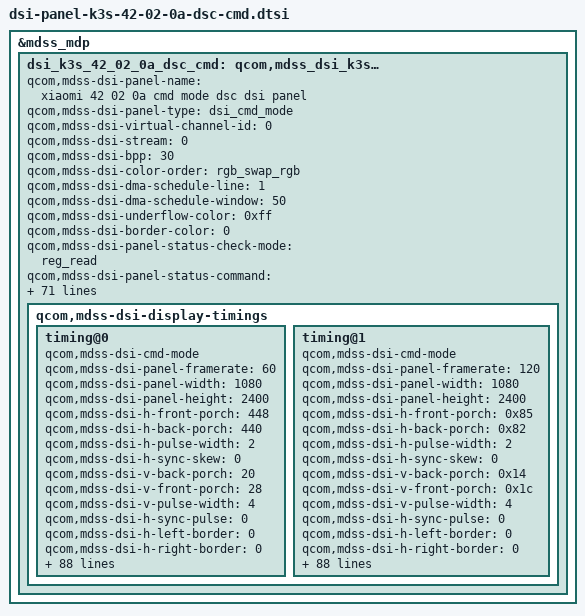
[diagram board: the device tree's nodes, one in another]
&mdss_mdp {
	dsi_k3s_42_02_0a_dsc_cmd: qcom,mdss_dsi_k3s_42_02_0a_dsc_cmd {
		qcom,mdss-dsi-panel-name = "xiaomi 42 02 0a cmd mode dsc dsi panel";
		qcom,mdss-dsi-panel-type = "dsi_cmd_mode";
		qcom,mdss-dsi-virtual-channel-id = <0>;
		qcom,mdss-dsi-stream = <0>;
		qcom,mdss-dsi-bpp = <30>;
		qcom,mdss-dsi-color-order = "rgb_swap_rgb";
		qcom,mdss-dsi-dma-schedule-line = <1>;
		qcom,mdss-dsi-dma-schedule-window = <50>;
		qcom,mdss-dsi-underflow-color = <0xff>;
		qcom,mdss-dsi-border-color = <0>;

		qcom,mdss-dsi-panel-status-check-mode = "reg_read";
		qcom,mdss-dsi-panel-status-command = <0x6010001 0x1fa 0x6010001 0x191>;
		qcom,mdss-dsi-panel-status-command-state = "dsi_lp_mode";
		qcom,mdss-dsi-panel-status-offset-command = [39 01 00 00 00 00 05 ff aa 55 a5 81 39 01 00 00 00 00 02 6f 0f];
		qcom,mdss-dsi-panel-status-offset-command-state = "dsi_lp_mode";
		qcom,mdss-dsi-panel-status-read-length = <0x01 0x12>;
		qcom,mdss-dsi-panel-status-value = <0 171 168
						0 12 194
						0 3 28 1 126
						0 15 8 187 4 61 16 240>;

		qcom,dsi-ctrl-num = <0>;
		qcom,dsi-phy-num = <0>;

		qcom,mdss-dsi-traffic-mode = "burst_mode";
		qcom,suspend-ulps-enabled;
		qcom,mdss-dsi-lane-map = "lane_map_0123";
		qcom,mdss-dsi-bllp-eof-power-mode;
		qcom,mdss-dsi-bllp-power-mode;
		qcom,mdss-dsi-lane-0-state;
		qcom,mdss-dsi-lane-1-state;
		qcom,mdss-dsi-lane-2-state;
		qcom,mdss-dsi-lane-3-state;
		qcom,mdss-dsi-dma-trigger = "trigger_sw";
		qcom,mdss-dsi-mdp-trigger = "none";
		qcom,mdss-dsi-reset-sequence = <0 10>, <1 10>, <0 1>, <1 10>;
		qcom,mdss-pan-physical-width-dimension = <695>;
		qcom,mdss-pan-physical-height-dimension = <1545>;
		qcom,mdss-dsi-te-pin-select = <1>;
		qcom,mdss-dsi-wr-mem-start = <0x2c>;
		qcom,mdss-dsi-wr-mem-continue = <0x3c>;
		qcom,mdss-dsi-te-dcs-command = <1>;
		qcom,mdss-dsi-te-check-enable;
		qcom,mdss-dsi-te-using-te-pin;
		qcom,mdss-dsi-tx-eot-append;
		qcom,mdss-dsi-lp11-init;

		qcom,mdss-dsi-panel-mode-switch;

		qcom,mdss-dsi-panel-max-error-count = <3>;

		qcom,mdss-dsi-bl-inverted-dbv;
		qcom,bl-update-flag = "delay_until_first_frame";

		qcom,mdss-dsi-panel-hdr-enabled;
		qcom,mdss-dsi-panel-hdr-color-primaries = <14500 15500 32000
			17000 15500 30000 8000 3000>;
		qcom,mdss-dsi-panel-peak-brightness = <4200000>;
		qcom,mdss-dsi-panel-blackness-level = <3230>;

		qcom,mdss-dsi-display-timings {
			timing@0 {
				qcom,mdss-dsi-cmd-mode;
				qcom,mdss-dsi-panel-framerate = <60>;
				qcom,mdss-dsi-panel-width = <1080>;
				qcom,mdss-dsi-panel-height = <2400>;
				qcom,mdss-dsi-h-front-porch = <448>;
				qcom,mdss-dsi-h-back-porch = <440>;
				qcom,mdss-dsi-h-pulse-width = <2>;
				qcom,mdss-dsi-h-sync-skew = <0>;
				qcom,mdss-dsi-v-back-porch = <20>;
				qcom,mdss-dsi-v-front-porch = <28>;
				qcom,mdss-dsi-v-pulse-width = <4>;
				qcom,mdss-dsi-h-sync-pulse = <0>;
				qcom,mdss-dsi-h-left-border = <0>;
				qcom,mdss-dsi-h-right-border = <0>;
				qcom,mdss-dsi-v-top-border = <0>;
				qcom,mdss-dsi-v-bottom-border = <0>;
				qcom,mdss-dsi-panel-clockrate = <1100000000>;
				qcom,mdss-dsi-panel-jitter = <0x5 0x1>;
				qcom,mdss-mdp-transfer-time-us = <14000>;
				qcom,mdss-dsi-on-command = [
					39 01 00 00 00 00 06 f0 55 aa 52 08 00 39 01 00 00 00 00 02 6f 05 39 01 00 00 00 00 02 be 08 39 01 00 00 00 00 02 90 01 39 01 00 00 00 00 13 91 ab a8 00 0c c2 00 03 1c 01 7e 00 0f 08 bb 04 3d 10 f0 39 01 00 00 00 00 02 03 01 39 01 00 00 00 00 02 2c 00 39 01 00 00 00 00 06 f0 55 aa 52 08 07 39 01 00 00 00 00 03 c0 01 02 39 01 00 00 00 00 02 35 00 39 01 00 00 00 00 05 2a 00 00 04 37 39 01 00 00 00 00 05 2b 00 00 09 5f 39 01 00 00 00 00 02 53 28 39 00 00 00 00 00 06 f0 55 aa 52 08 00 39 00 00 00 00 00 02 6f 02 39 01 00 00 00 00 03 b2 08 08 39 01 00 00 00 00 02 2f 01 39 01 00 00 00 00 06 f0 55 aa 52 08 01 39 01 00 00 00 00 08 c3 9b 01 94 d0 22 02 00 39 01 00 00 00 00 06 f0 55 aa 52 08 00 39 01 00 00 00 00 02 6f 06 39 01 00 00 00 00 04 b5 2b 0c 32 39 01 00 00 78 00 02 11 00 39 01 00 00 00 00 02 29 00
				];
				qcom,mdss-dsi-on-command-state = "dsi_lp_mode";

				qcom,mdss-dsi-nolp-command = <0x39010000 0x551 0x00 0x39000000 0x6f0 0x55aa5208 0x390000 0x02 0xb2183900 0x00 0x2650039 0x00 0x23800 0x39000000 0x22c 0x390000 0x02 0x2f013900 0x00 0x6f055aa 0x52080139 0x1000000 0x2ce0c>;
				qcom,mdss-dsi-nolp-command-state = "dsi_lp_mode";
				qcom,mdss-dsi-off-command = [
					39 01 00 00 00 00 02 28 00 39 01 00 00 64 00 02 10 00
				];
				qcom,mdss-dsi-off-command-state = "dsi_lp_mode";

				qcom,mdss-dsi-panel-phy-timings = [00 24 0a 0a 1a 24 0a 0a 0a 09 02 04 1e 0f];
				qcom,mdss-dsi-timing-switch-command = [
					/* Frame Rate 60Hz */
					39 01 00 00 09 00 02 2f 01
				];
				qcom,mdss-dsi-timing-switch-command-state = "dsi_lp_mode";

				qcom,default-topology-index = <0>;
				qcom,display-topology = <1 1 1>;

				qcom,compression-mode = "dsc";
				qcom,mdss-dsc-version = <18>;
				qcom,mdss-dsc-scr-version = <0>;
				qcom,mdss-dsc-slice-height = <12>;
				qcom,mdss-dsc-slice-width = <1080>;
				qcom,mdss-dsc-slice-per-pkt = <2>;
				qcom,mdss-dsc-bit-per-component = <10>;
				qcom,mdss-dsc-bit-per-pixel = <8>;
				qcom,mdss-dsc-block-prediction-enable;
			};
			timing@1 {
				qcom,mdss-dsi-cmd-mode;
				qcom,mdss-dsi-panel-framerate = <120>;
				qcom,mdss-dsi-panel-width = <1080>;
				qcom,mdss-dsi-panel-height = <2400>;
				qcom,mdss-dsi-h-front-porch = <0x85>;
				qcom,mdss-dsi-h-back-porch = <0x82>;
				qcom,mdss-dsi-h-pulse-width = <2>;
				qcom,mdss-dsi-h-sync-skew = <0>;
				qcom,mdss-dsi-v-back-porch = <0x14>;
				qcom,mdss-dsi-v-front-porch = <0x1c>;
				qcom,mdss-dsi-v-pulse-width = <4>;
				qcom,mdss-dsi-h-sync-pulse = <0>;
				qcom,mdss-dsi-h-left-border = <0>;
				qcom,mdss-dsi-h-right-border = <0>;
				qcom,mdss-dsi-v-top-border = <0>;
				qcom,mdss-dsi-v-bottom-border = <0>;
				qcom,mdss-dsi-panel-clockrate = <1100000000>;
				qcom,mdss-dsi-panel-jitter = <0x5 0x1>;
				qcom,mdss-mdp-transfer-time-us = <7000>;
				qcom,mdss-dsi-on-command = [
					39 01 00 00 00 00 06 f0 55 aa 52 08 00 39 01 00 00 00 00 02 6f 05 39 01 00 00 00 00 02 be 08 39 01 00 00 00 00 02 90 01 39 01 00 00 00 00 13 91 ab a8 00 0c c2 00 03 1c 01 7e 00 0f 08 bb 04 3d 10 f0 39 01 00 00 00 00 02 03 01 39 01 00 00 00 00 02 2c 00 39 01 00 00 00 00 06 f0 55 aa 52 08 07 39 01 00 00 00 00 03 c0 01 02 39 01 00 00 00 00 02 35 00 39 01 00 00 00 00 05 2a 00 00 04 37 39 01 00 00 00 00 05 2b 00 00 09 5f 39 01 00 00 00 00 02 53 28 39 00 00 00 00 00 06 f0 55 aa 52 08 00 39 00 00 00 00 00 02 6f 02 39 01 00 00 00 00 03 b2 08 08 39 01 00 00 00 00 02 2f 02 39 01 00 00 00 00 06 f0 55 aa 52 08 01 39 01 00 00 00 00 08 c3 9b 01 94 d0 22 02 00 39 01 00 00 00 00 06 f0 55 aa 52 08 00 39 01 00 00 00 00 02 6f 06 39 01 00 00 00 00 04 b5 2b 0c 32 39 01 00 00 78 00 02 11 00 39 01 00 00 00 00 02 29 00
				];
				qcom,mdss-dsi-on-command-state = "dsi_lp_mode";

				qcom,mdss-dsi-off-command = [
					39 01 00 00 00 00 02 28 00
					39 01 00 00 64 00 02 10 00];
				qcom,mdss-dsi-off-command-state = "dsi_lp_mode";

				qcom,mdss-dsi-timing-switch-command = [
					/* Frame Rate 90Hz */
					39 01 00 00 11 00 02 2f 02
				];
				qcom,mdss-dsi-timing-switch-command-state = "dsi_lp_mode";

				qcom,compression-mode = "dsc";
				qcom,mdss-dsc-version = <18>;
				qcom,mdss-dsc-scr-version = <0x0>;
				qcom,mdss-dsi-panel-phy-timings = [00 24 0a 0a 1a 19 09 0a 0a 09 02 04 1e 0f];
				qcom,mdss-dsc-slice-height = <12>;
				qcom,mdss-dsc-slice-width = <1080>;
				qcom,mdss-dsc-slice-per-pkt = <2>;
				qcom,mdss-dsc-bit-per-component = <10>;
				qcom,mdss-dsc-bit-per-pixel = <8>;
				qcom,mdss-dsc-block-prediction-enable;
				qcom,default-topology-index = <0x00>;
				qcom,display-topology = <1 1 1>;
				qcom,mdss-dsi-nolp-command = <0x39010000 0x551 0x00 0x39000000 0x6f0 0x55aa5208 0x390000 0x02 0xb2183900 0x00 0x2650039 0x00 0x23800 0x39000000 0x22c 0x390000 0x02 0x2f023900 0x00 0x6f055aa 0x52080139 0x1000000 0x2ce0c>;
				qcom,mdss-dsi-nolp-command-state = "dsi_lp_mode";
			};
		};
	};
};

&dsi_k3s_42_02_0a_dsc_cmd {
	mi,panel-id = <0x00004B3353 0x0000420200>;
	mi,hbm-51-ctl-flag;
	mi,hbm-off-51-index = <0>;
	mi,hbm-on-51-index = <0>;
	mi,hbm-bl-min-level = <1>;
	mi,hbm-bl-max-level = <2047>;
	mi,max-brightness-clone = <8191>;
	// mi,fp-display-on-optimize-flag;
	mi,aod-hbm-51-index = <8>;
	mi,aod-lbm-51-index = <8>;
	mi,mdss-dsi-panel-dc-type = <0>;
	mi,dc-off-120hz-d4-index = <7>;
	mi,dc-off-60hz-d2-index = <6>;
	mi,dc-on-120hz-d4-index = <11>;
	mi,dc-on-60hz-d2-index = <10>;

	mi,dc-update-flag;
	mi,esd-err-irq-gpio = <&tlmm 75 8193>;
	mi,flatmode-on-b9-index = <0x03>;
	mi,flatmode-update-flag;
	mi,fp-display-on-optimize-flag;
	//mi,panel-hbm-backlight-threshold = <2047>;
	//mi,panel-cup-dbi-reg-index = <1>;

	mi,panel-on-dimming-delay = <120>;

	mi,panel-aod-to-off-command-need-enabled;
	//mi,thermal-dimming-flag;

	qcom,dsi-select-clocks = "mux_byte_clk0", "mux_pixel_clk0";
	qcom,mdss-dsi-clk-strength = <101>;
	qcom,esd-aod-check-enabled;
	qcom,esd-check-enabled;

	qcom,mdss-dsi-display-timings {
		timing@0 {
			mi,mdss-dsc-panel-id = <0x00004B3353 0x00420200>;
			mi,mdss-dsi-dimmingon-command = [39 01 00 00 00 00 02 53 28];
			mi,mdss-dsi-dimmingon-command-state = "dsi_hs_mode";
			mi,mdss-dsi-dimmingoff-command = [39 01 00 00 00 00 02 53 20];
			mi,mdss-dsi-dimmingoff-command-state = "dsi_hs_mode";

			mi,mdss-dsi-hbm-on-command = [39 01 00 00 00 00 03 51 0F FF];
			mi,mdss-dsi-hbm-on-command-state = "dsi_lp_mode";
			mi,mdss-dsi-hbm-off-command = [39 01 00 00 00 00 03 51 07 FF];
			mi,mdss-dsi-hbm-off-command-state = "dsi_lp_mode";

			mi,mdss-dsi-doze-hbm-command = [
				/* Frame Rate 60Hz */
				39 01 00 00 00 00 02 2f 01
				39 00 00 00 00 00 06 f0 55 aa 52 08 08
				39 00 00 00 00 00 02 6f 07
				39 00 00 00 00 00 05 b9 00 00 00 3d
				39 00 00 00 00 00 06 f0 55 aa 52 08 00
				39 00 00 00 00 00 02 b2 08
				39 01 00 00 32 00 02
				39 00 39 00 00 00 00 00 02 65 01
				39 01 00 00 00 00 05 51 01 06 0f ff
			];
			mi,mdss-dsi-doze-hbm-command-state = "dsi_lp_mode";
			mi,mdss-dsi-doze-lbm-command = [
				/* Frame Rate 60Hz */
				39 01 00 00 00 00 02 2f 01 39 00 00 00 00 00 06 f0 55 aa 52 08 08 39 00 00 00 00 00 02 6f 07 39 00 00 00 00 00 05 b9 00 00 00 3d 39 00 00 00 00 00 06 f0 55 aa 52 08 00 39 00 00 00 00 00 02 b2 08 39 01 00 00 32 00 02 39 00 39 00 00 00 00 00 02 65 01 39 01 00 00 00 00 05 51 00 24 01 55
			];
			mi,mdss-dsi-doze-lbm-command-state = "dsi_lp_mode";

			mi,mdss-dsi-flat-mode-on-command = [
				39 00 00 00 00 00 02 2f 03 39 00 00 00 00 00 06 f0 55 aa 52 08 08 39 00 00 00 00 00 02 6f 07 39 00 00 00 00 00 05 b9 00 00 00 00 39 00 00 00 00 00 06 f0 55 aa 52 08 00 39 00 00 00 00 00 02 6f 08 39 01 00 00 00 00 02 c0 44
			];
			mi,mdss-dsi-flat-mode-on-command-state = "dsi_hs_mode";
			mi,mdss-dsi-flat-mode-off-command = [
				39 00 00 00 00 00 02 2f 01 39 00 00 00 00 00 06 f0 55 aa 52 08 08 39 00 00 00 00 00 02 6f 07 39 00 00 00 00 00 05 b9 00 00 00 3d 39 00 00 00 00 00 06 f0 55 aa 52 08 00 39 00 00 00 00 00 02 6f 08 39 01 00 00 00 00 02 c0 40
			];
			mi,mdss-dsi-flat-mode-off-command-state = "dsi_hs_mode";

			mi,mdss-dsi-flat-mode-read-pre-command = [39 01 00 00 00 00 06 f0 55 aa 52 08 00 39 01 00 00 00 00 02 6f 3f];
			mi,mdss-dsi-flat-mode-read-pre-command-state = "dsi_lp_mode";

			mi,mdss-dsi-aod-to-dc-on-command = [
				39 01 00 00 00 00 06 f0 55 aa 52 08 00
				39 01 00 00 00 00 02 b2 98
			];
			mi,mdss-dsi-aod-to-dc-on-command-state = "dsi_hs_mode";

			mi,mdss-dsi-dc-on-command = [
				39 01 00 00 00 00 06 f0 55 aa 52 08 00
				39 00 00 00 00 00 02 b2 98
				39 00 00 00 00 00 02 6f 0f
				39 00 00 00 00 00 09 b2 00 00 01 47 01 47 00 00
				39 00 00 00 00 00 25 b3 00
							00 00 00 00 00 00 00 00
							00 00 00 00 00 00 00 00
							00 00 00 00 00 00 00 00
							00 00 00 00 00 00 00 07 ff 0f ff
				39 00 00 00 00 00 02 6f ac
				39 00 00 00 00 00 47 b2 00
				00 01 0a 01 6c 01 b6 01 f3
				02 28 02 58 02 84 02 ac 02
				d2 02 f5 03 17 03 37 04 e0
				06 09 06 fa 07 c9 08 81 09
				28 09 c1 0a 51 0a d7 0b 56
				0b cf 0c 42 0c b0 0d 1a 0d
				80 0d e3 0e 42 0e 9f 0e f9
				0f 50 0f a5 0f ff
				39 00 00 00 00 00 02 6f 52
				39 00 00 00 00 00 45 b3 00 05 00 0a 00 0f 00 14 00 19 00 1e 00 23 00 28 00 2d 00 32 00 37 00 3c 00 96 00 f0 01 4a 01 a4 01 fe 02 58 02 b2 03 0c 03 66 03 c0 04 1a 04 74 04 ce 05 28 05 82 05 dc 06 36 06 90 06 ea 07 44 07 9e 07 ff
				39 00 00 00 00 00 06 f0 55 aa 52 08 04
				39 00 00 00 00 00 4c d2 00 00 00 00 00 00 00 00 00 00 00 00 00 00 00 00 00 00 00 00 00 00 00 00 00 00 00 00 00 00 00 00 00 00 00 00 00 00 00 00 00 00 00 00 00 00 00 00 00 00 00 00 00 00 00 00 00 00 00 00 00 00 00 00 00 00 00 00 00 00 00 00 00 00 00
				39 01 00 00 00 00 4c d4 00 00 00 00 00 00 00 00 00 00 00 00 00 00 00 00 00 00 00 00 00 00 00 00 00 00 00 00 00 00 00 00 00 00 00 00 00 00 00 00 00 00 00 00 00 00 00 00 00 00 00 00 00 00 00 00 00 00 00 00 00 00 00 00 00 00 00 00 00 00 00 00 00 00 00
			];
			mi,mdss-dsi-dc-on-command-state = "dsi_lp_mode";
			mi,mdss-dsi-dc-off-command = [
				39 01 00 00 00 00 06 f0 55 aa 52 08 00
				39 00 00 00 00 00 02 b2 18
				39 00 00 00 00 00 02 6f 0f
				39 00 00 00 00 00 09 b2 20 20 21 47 21 47 20 00
				39 00 00 00 00 00 25 b3 00 08 00 18 00 18 00
				31 00 31 00 62 00 62 00 c0 00 c0 01 32 01 32 01 47 01 47 03 33 03 33 07 ff 07 ff 0f ff
				39 00 00 00 00 00 06 f0 55 aa 52 08 04
				39 00 00 00 00 00 4c d2
				00 00 00 00 00 00 00 00
				00 00 00 00 00 00 00 00
				00 00 00 00 00 00 00 00
				00 00 00 00 00 00 00 00
				00 00 00 00 00 00 00 00
				00 00 00 00 00 00 00 00
				00 00 00 00 00 00 00 00
				00 00 00 00 00 00 00 00
				00 00 00 00 00 00 00 00 00 00 00
				39 01 00 00 00 00 4c d4 00 00 00
				00 00 00 00 00 00 00 00
				00 00 00 00 00 00 00 00
				00 00 00 00 00 00 00 00
				00 00 00 00 00 00 00 00
				00 00 00 00 00 00 00 00
				00 00 00 00 00 00 00 00
				00 00 00 00 00 00 00 00
				00 00 00 00 00 00 00 00
				00 00 00 00 00 00 00 00
			];
			mi,mdss-dsi-dc-off-command-state = "dsi_lp_mode";

			mi,mdss-dsi-pre-doze-to-off-command = [39 01 00 00 00 00 06 f0 55 aa 52 08 01 39 01 00 00 00 00 02 ce 0c];
			mi,mdss-dsi-pre-doze-to-off-command-state = "dsi_lp_mode";
			mi,mdss-dsi-switch-page4-command = [39 01 00 00 00 00 06 f0 55 aa 52 08 04];
			mi,mdss-dsi-switch-page4-command-state = "dsi_lp_mode";
			mi,mdss-dsi-timing-switch-gir-command = [39 01 00 00 09 00 02 2f 03];
			mi,mdss-dsi-timing-switch-gir-command-state = "dsi_hs_mode";
		};
		timing@1 {
			mi,mdss-dsc-panel-id = <0x00004B3353 0x00420200>;
			mi,mdss-dsi-dimmingon-command = [39 01 00 00 00 00 02 53 28];
			mi,mdss-dsi-dimmingon-command-state = "dsi_hs_mode";
			mi,mdss-dsi-dimmingoff-command = [39 01 00 00 00 00 02 53 20];
			mi,mdss-dsi-dimmingoff-command-state = "dsi_hs_mode";

			mi,mdss-dsi-aod-to-dc-on-command = [39 01 00 00 00 00 06 f0 55 aa 52 08 00 39 01 00 00 00 00 02 b2 98];
			mi,mdss-dsi-aod-to-dc-on-command-state = "dsi_hs_mode";

			mi,mdss-dsi-doze-hbm-command = [
				/* Frame Rate 60Hz */
				39 01 00 00 00 00 02 2f 01 39 00 00 00 00 00 06 f0 55 aa 52 08 08 39 00 00 00 00 00 02 6f 07 39 00 00 00 00 00 05 b9 00 00 00 3d 39 00 00 00 00 00 06 f0 55 aa 52 08 00 39 00 00 00 00 00 02 b2 08 39 01 00 00 32 00 02 39 00 39 00 00 00 00 00 02 65 01 39 01 00 00 00 00 05 51 01 06 0f ff
			];
			mi,mdss-dsi-doze-hbm-command-state = "dsi_lp_mode";
			mi,mdss-dsi-doze-lbm-command = [
				/* Frame Rate 60Hz */
				39 01 00 00 00 00 02 2f 01 39 00 00 00 00 00 06 f0 55 aa 52 08 08 39 00 00 00 00 00 02 6f 07 39 00 00 00 00 00 05 b9 00 00 00 3d 39 00 00 00 00 00 06 f0 55 aa 52 08 00 39 00 00 00 00 00 02 b2 08 39 01 00 00 32 00 02 39 00 39 00 00 00 00 00 02 65 01 39 01 00 00 00 00 05 51 00 24 01 55
			];

			mi,mdss-dsi-hbm-off-command = [39 01 00 00 00 00 03 51 07 ff];
			mi,mdss-dsi-hbm-off-command-state = "dsi_lp_mode";
			mi,mdss-dsi-hbm-on-command = [39 01 00 00 00 00 03 51 0f ff];
			mi,mdss-dsi-hbm-on-command-state = "dsi_lp_mode";

			mi,mdss-dsi-doze-lbm-command-state = "dsi_lp_mode";

			mi,mdss-dsi-flat-mode-on-command = [
				39 00 00 00 00 00 02 2f 04 39 00 00 00 00 00 06 f0 55 aa 52 08 08 39 00 00 00 00 00 02 6f 07 39 00 00 00 00 00 05 b9 00 00 00 00 39 00 00 00 00 00 06 f0 55 aa 52 08 00 39 00 00 00 00 00 02 6f 08 39 01 00 00 00 00 02 c0 44
			];
			mi,mdss-dsi-flat-mode-on-command-state = "dsi_hs_mode";
			mi,mdss-dsi-flat-mode-off-command = [
				39 00 00 00 00 00 02 2f 02 39 00 00 00 00 00 06 f0 55 aa 52 08 08 39 00 00 00 00 00 02 6f 07 39 00 00 00 00 00 05 b9 00 00 00 3d 39 00 00 00 00 00 06 f0 55 aa 52 08 00 39 00 00 00 00 00 02 6f 08 39 01 00 00 00 00 02 c0 40
			];
			mi,mdss-dsi-flat-mode-off-command-state = "dsi_hs_mode";

			mi,mdss-dsi-flat-mode-read-pre-command = [39 01 00 00 00 00 06 f0 55 aa 52 08 00 39 01 00 00 00 00 02 6f 3f];
			mi,mdss-dsi-flat-mode-read-pre-command-state = "dsi_lp_mode";

			mi,mdss-dsi-dc-on-command = [
				39 01 00 00 00 00 06 f0 55 aa 52 08 00 39 00 00 00 00 00 02 b2 98 39 00 00 00 00 00 02 6f 0f 39 00 00 00 00 00 09 b2 00 00 01 47 01 47 00 00 39 00 00 00 00 00 25 b3 00 00 00 00 00 00 00 00 00 00 00 00 00 00 00 00 00 00 00 00 00 00 00 00 00 00 00 00 00 00 00 00 07 ff 0f ff 39 00 00 00 00 00 02 6f ac 39 00 00 00 00 00 47 b2 00 00 01 0a 01 6c 01 b6 01 f3 02 28 02 58 02 84 02 ac 02 d2 02 f5 03 17 03 37 04 e0 06 09 06 fa 07 c9 08 81 09 28 09 c1 0a 51 0a d7 0b 56 0b cf 0c 42 0c b0 0d 1a 0d 80 0d e3 0e 42 0e 9f 0e f9 0f 50 0f a5 0f ff 39 00 00 00 00 00 02 6f 52 39 00 00 00 00 00 45 b3 00 05 00 0a 00 0f 00 14 00 19 00 1e 00 23 00 28 00 2d 00 32 00 37 00 3c 00 96 00 f0 01 4a 01 a4 01 fe 02 58 02 b2 03 0c 03 66 03 c0 04 1a 04 74 04 ce 05 28 05 82 05 dc 06 36 06 90 06 ea 07 44 07 9e 07 ff 39 00 00 00 00 00 06 f0 55 aa 52 08 04 39 00 00 00 00 00 4c d2 00 00 00 00 00 00 00 00 00 00 00 00 00 00 00 00 00 00 00 00 00 00 00 00 00 00 00 00 00 00 00 00 00 00 00 00 00 00 00 00 00 00 00 00 00 00 00 00 00 00 00 00 00 00 00 00 00 00 00 00 00 00 00 00 00 00 00 00 00 00 00 00 00 00 00 39 01 00 00 00 00 4c d4 00 00 00 00 00 00 00 00 00 00 00 00 00 00 00 00 00 00 00 00 00 00 00 00 00 00 00 00 00 00 00 00 00 00 00 00 00 00 00 00 00 00 00 00 00 00 00 00 00 00 00 00 00 00 00 00 00 00 00 00 00 00 00 00 00 00 00 00 00 00 00 00 00 00 00
			];
			mi,mdss-dsi-dc-on-command-state = "dsi_lp_mode";
			mi,mdss-dsi-dc-off-command = [
				39 01 00 00 00 00 06 f0 55 aa 52 08 00 39 00 00 00 00 00 02 b2 18 39 00 00 00 00 00 02 6f 0f 39 00 00 00 00 00 09 b2 30 20 31 47 21 47 20 00 39 00 00 00 00 00 25 b3 00 08 00 18 00 18 00 31 00 31 00 62 00 62 00 c0 00 c0 01 32 01 32 01 47 01 47 03 33 03 33 07 ff 07 ff 0f ff 39 00 00 00 00 00 06 f0 55 aa 52 08 04 39 00 00 00 00 00 4c d2 00 00 00 00 00 00 00 00 00 00 00 00 00 00 00 00 00 00 00 00 00 00 00 00 00 00 00 00 00 00 00 00 00 00 00 00 00 00 00 00 00 00 00 00 00 00 00 00 00 00 00 00 00 00 00 00 00 00 00 00 00 00 00 00 00 00 00 00 00 00 00 00 00 00 00 39 01 00 00 00 00 4c d4 00 00 00 00 00 00 00 00 00 00 00 00 00 00 00 00 00 00 00 00 00 00 00 00 00 00 00 00 00 00 00 00 00 00 00 00 00 00 00 00 00 00 00 00 00 00 00 00 00 00 00 00 00 00 00 00 00 00 00 00 00 00 00 00 00 00 00 00 00 00 00 00 00 00 00
			];
			mi,mdss-dsi-dc-off-command-state = "dsi_lp_mode";

			mi,mdss-dsi-pre-doze-to-off-command = [39 01 00 00 00 00 06 f0 55 aa 52 08 01 39 01 00 00 00 00 02 ce 0c];
			mi,mdss-dsi-pre-doze-to-off-command-state = "dsi_lp_mode";
			mi,mdss-dsi-switch-page4-command = [39 01 00 00 00 00 06 f0 55 aa 52 08 04];
			mi,mdss-dsi-switch-page4-command-state = "dsi_lp_mode";
			mi,mdss-dsi-timing-switch-gir-command = [39 01 00 00 11 00 02 2f 04];
			mi,mdss-dsi-timing-switch-gir-command-state = "dsi_hs_mode";
		};
	};
};
